# cslr_usb_001 register map
Vendor: Texas Instruments
Peripheral module from a debugger description file.
Registers are 32-bit, access not given, reset values left out (the file's numbers can be read two ways) unless marked. A register's access mark holds for its fields unless they carry their own. Offsets are as the file gives them; lines under a group give offsets from that group; [hi:lo] are bit positions; {n}, {i} and the like mark numbered series; 'fields as' and 'values as' point back to an identical list; <NAME> marks a mode.

## USB (part 1 of 2) — USB2.0 OTG Controller
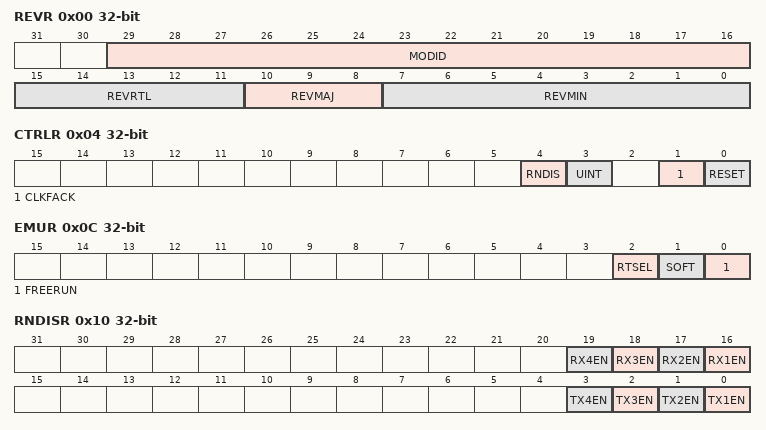
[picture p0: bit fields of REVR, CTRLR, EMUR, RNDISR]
0x00 REVR — Revision Register
  [29:16] MODID ro — Module ID field
  [15:11] REVRTL rw — RTL version
  [10:8] REVMAJ rw — Major revision
  [7:0] REVMIN rw — Minor revision.
0x04 CTRLR — Control Register
  [4] RNDIS rw — RNDIS mode enable
  [3] UINT rw — USB non-PDR interrupt enable
  [1] CLKFACK rw — Clock stop fast ack enable
  [0] RESET wo — Soft reset Writing a 1 starts a module reset
0x08 STATR — Status Register
  [0] DRVVBUS ro — Current DRVVBUS value
0x0C EMUR — Emulation Register to configure CBA3.0 interface
  [2] RTSEL rw — Real-time Enable
  [1] SOFT rw — Soft Stop Enable
  [0] FREERUN rw — Free Run Enable
0x10 RNDISR — RNDIS Register to enable RNDIS mode for each endpoint. Using the global RNDIS enable (RNDIS bit of CTRLR) overrides thie register and enable RNDIS mode for all endpoints
  [n+15] RX{n}EN rw (n=1..4) — Rx Endpoint {n} RNDIS mode enable
  [n-1] TX{n}EN rw (n=1..4) — TX Endpoint {n} RNDIS mode enable
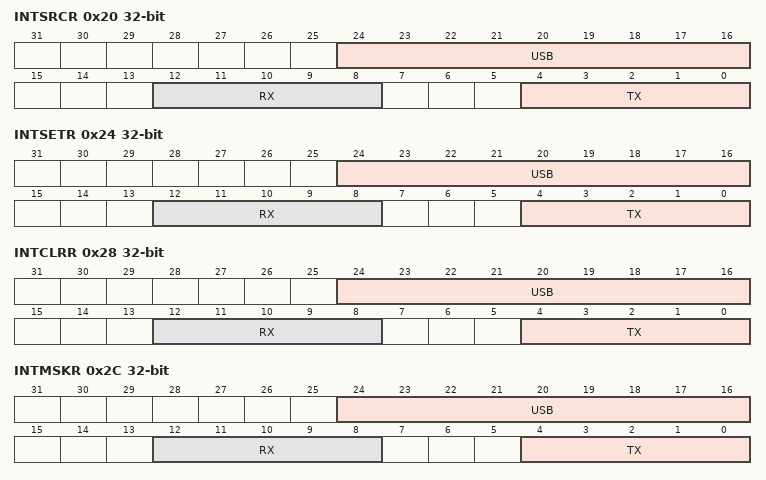
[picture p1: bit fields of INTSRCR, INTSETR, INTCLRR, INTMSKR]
0x20 INTSRCR — USB Interrupt Source Register
  [24:16] USB ro — USB interrupt sources Generated by the USB core (not the DMA)
  [12:8] RX ro — RX endpoint interrupt sources Generated by the USB core (not the DMA)
  [4:0] TX ro — TX endpoint interrupt sources Generated by the USB core (not the DMA)
0x24 INTSETR — USB Interrupt Source Set Register
  [24:16] USB wo — Write a 1 to set equivalent USB interrupt source Allows the USB interrupt sources to be manually triggered
  [12:8] RX wo — Write a 1 to set equivalent RX endpoint interrupt source Allows the USB interrupt sources to be manually triggered
  [4:0] TX wo — Write a 1 to set equivalent TX endpoint interrupt source Allows the USB interrupt sources to be manually triggered
0x28 INTCLRR — USB Interrupt Source Clear Register
  [24:16] USB wo — Write a 1 to clear equivalent USB interrupt source Allows the CPU to acknowledge an interrupt source and turn it off
  [12:8] RX wo — Write a 1 to clear equivalent RX endpoint interrupt source Allows the CPU to acknowledge an interrupt source and turn it off
  [4:0] TX wo — Write a 1 to clear equivalent TX endpoint interrupt source Allows the CPU to acknowledge an interrupt source and turn it off
0x2C INTMSKR — USB Interrupt Mask Register
  [24:16] USB ro — USB interrupt source masks Contains the masks of the interrupt sources generated by the USB core (not the DMA). These masks are used to enable or disable interrupt sources appearing as masked interrupts
  [12:8] RX ro — RX endpoint interrupt source masks Contains the masks of the interrupt sources generated by the USB core (not the DMA). These masks are used to enable or disable interrupt sources appearing as masked interrupts
  [4:0] TX ro — TX endpoint interrupt source masks Contains the masks of the interrupt sources generated by the USB core (not the DMA). These masks are used to enable or disable interrupt sources appearing as masked interrupts
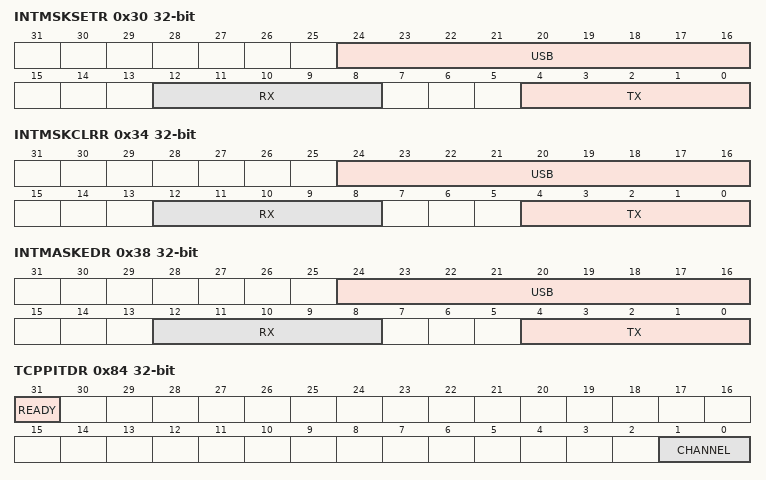
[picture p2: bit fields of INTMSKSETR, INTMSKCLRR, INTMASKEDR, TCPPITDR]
0x30 INTMSKSETR — USB Interrupt Mask Set Register
  [24:16] USB wo — Write a 1 to set equivalent USB interrupt mask Allows the USB interrupt masks to be individually enabled
  [12:8] RX wo — Write a 1 to set equivalent RX endpoint interrupt mask Allows the USB interrupt masks to be individually enabled
  [4:0] TX wo — Write a 1 to set equivalent TX endpoint interrupt mask Allows the USB interrupt masks to be individually enabled
0x34 INTMSKCLRR — USB Interrupt Mask Clear Register
  [24:16] USB wo — Write a 1 to clear equivalent USB interrupt mask Allows the USB interrupt masks to be individually disabled
  [12:8] RX wo — Write a 1 to clear equivalent RX endpoint interrupt mask Allows the USB interrupt masks to be individually disabled
  [4:0] TX wo — Write a 1 to clear equivalent TX endpoint interrupt mask Allows the USB interrupt masks to be individually disabled
0x38 INTMASKEDR — USB Interrupt Source Masked Register
  [24:16] USB ro — USB interrupt sources masked Contains the status of the interrupt sources generated by the USB core masked by the USB Interrupt Mask Register values
  [12:8] RX ro — RX endpoint interrupt sources masked Contains the status of the interrupt sources generated by the USB core masked by the USB Interrupt Mask Register values
  [4:0] TX ro — TX endpoint interrupt sources masked Contains the status of the interrupt sources generated by the USB core masked by the USB Interrupt Mask Register values
0x3C EOIR — USB End of Interrupt Register
  [7:0] VECTOR rw — EOI Vector Allows the CPU to acknowledge completion of an interrupt by writing to the EOI. An eoi_write signal will be generated, the EOI vector will be updated to the written value, and another interrupt will be triggered if interrupt sources remain
0x40 INTVECTR ro — USB Interrupt Vector Register
  [31:0] VECTOR — Input Interrupt Vector Recycles the Interrupt Vector input to be read by the CPU
0x80 TCPPICR — Tx CPPI Control Register
  [0] TCPPI_ENABLE rw — Tx CPPI Enable Controls if the Tx CPPI DMA controller is enabled 0: Tx CPPI DMA is disabled 1: Tx CPPI DMA is enabled
0x84 TCPPITDR — Tx CPPI Teardown Register
  [31] READY ro — Indicates if the Teardown register can be written
  [1:0] CHANNEL rw — Teardown Channel Indicates the channel that is to be torn down
0x88 TCPPIEOIR access per field — Tx CPPI DMA Controller End of Interrupt Register
  [7:0] VECTOR rw — End of Interrupt Vector This is an application specific register which is essentially a general purpose output from the LCSAR. One cycle after this register is written, the eoi_vector[7:0] value will appear on the eoi_vector output port from the LCSAR and the eoi_write output port will be assserted for 1 clock cycle. This register is used to convert level sensitive interrupts to pulsed, non-redundant interrupts
0x8C TCPPIIVECTR ro — Tx CPPI DMA Controller Interrupt Vector Register
  [31:0] VECTOR — Interrupt Vector This is an application specific register which is essentially a general purpose input to the LCSAR. The intr_vector field in this register is a registered version of the intr_vector primary input to the LCSAR. This register is used for interrupt handling
0x90 TCPPIMSKSR — Tx CPPI Masked Status Register
  [3:0] COMP_PENDING ro — Masked High Priority Transmit Completion Pending Indicators for channels 3 to 0 Raw Tx high priority completion indicators bitwise anded with Tx high priority completion mask bits
0x94 TCPPIRAWSR — Tx CPPI Raw Status Register
  [3:0] COMP_PENDING ro — Raw High Priority Transmit Completion Pending Indicators for channels 3 to 0 Active high flags which indicate that a packet has completed transmission on the high priority queue
0x98 TCPPIIENSETR — Tx CPPI Interrupt Enable Set Register
  [3:0] COMP_PENDING_INTR_EN rw — Tx CPPI High Priority Interrupt Enables These are active high interrupt enables corresponding to the Tx CPPI High Priority Completion Pending status bits
0x9C TCPPIIENCLRR — Tx CPPI Interrupt Enable Clear Register
  [3:0] COMP_PENDING_INTR_EN rw — Writing a 1 to any of the bits in the Tx CPPI Interrupt Enable Clear Register will result in clearing of the corresponding bit in the Tx CPPI High Priority Interrupt Enable Register
0xC0 RCPPICR — Rx CPPI Control Register
  [0] RCPPI_ENABLE rw — Rx CPPI Enable Controls if the Rx CPPI DMA controller is enabled 0: Rx CPPI DMA is disabled 1: Rx CPPI DMA is enabled
0xD0 RCPPIMSKSR — Rx CPPI Masked Status Register
  [3:0] MASKED_COMP_PENDING ro — Masked Receive Completion Pending Indicators for channels 3 to 0 Raw Rx completion indicators bitwise ANDed with Rx completion mask bits
0xD4 RCPPIRAWSR — Rx CPPI Raw Status Register
  [3:0] COMP_PENDING ro — Raw Receive Completion Pending Indicators for channels 3 to 0 Active high flags which indicate that a packet has completed reception
0xD8 RCPPIENSETR — Rx CPPI Interrupt Enable Set Register
  [3:0] COMP_PENDING_INTR_EN rw — Rx CPPI Interrupt Enables These are active high interrupt enables corresponding to the Rx CPPI Completion Pending status bits Writing a 1 to any of the bits in the Rx CPPI Interrupt Enable Set Register will result in setting of the corresponding bit in the Rx CPPI Interrupt Enable Register
0xDC RCPPIIENCLRR — Rx CPPI Interrupt Enable Clear Register
  [3:0] COMP_PENDING_INTR_EN rw — Rx CPPI Interrupt Enables These are active high interrupt enables corresponding to the Rx CPPI Completion Pending status bits Writing a 1 to any of the bits in the Rx CPPI Interrupt Enable Clear Register will result in clearing of the corresponding bit in the Rx CPPI Interrupt Enable Register
{0xE0+4i} RBUFCNT{i} (i=0..2) — Rx Buffer Count {i} Register
  [15:0] BUFCNT rw — Rx CPPI Buffer Count The current count of CPPI buffers in Rx channel {i} queue. Writes add to current value (not overwrite)
0xEC RBUFCNT3 — Rx Buffer Count 3 Register
  [15:0] BUFCNT rw — Rx CPPI Buffer Count 0 The current count of CPPI buffers in Rx channel 3 queue. Writes add to current value (not overwrite)
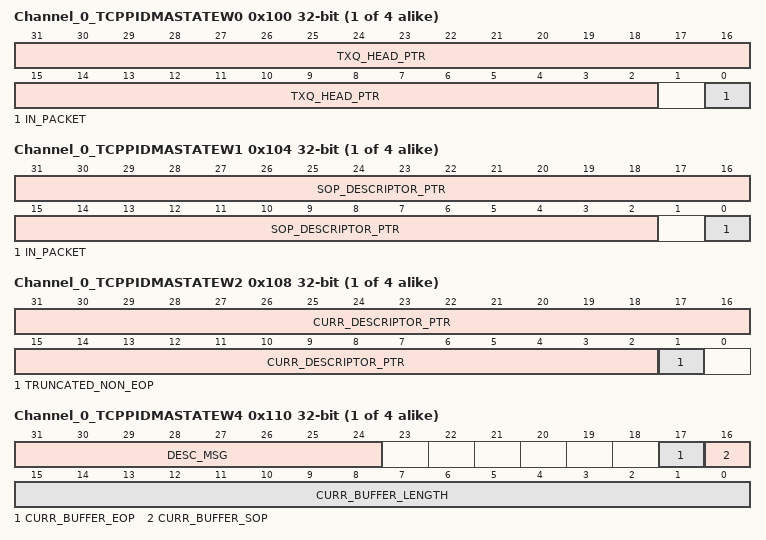
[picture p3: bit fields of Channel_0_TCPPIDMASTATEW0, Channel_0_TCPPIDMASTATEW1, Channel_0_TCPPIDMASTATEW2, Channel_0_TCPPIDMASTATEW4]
{0x100+0x40*i} Channel_{i}_TCPPIDMASTATEW0 (i=0..3) — TX CPPI DMA State Word 0
  [31:2] TXQ_HEAD_PTR rw — TX queue head pointer 30 bit pointer to 32-bit aligned descriptor at the head of the high priority TX queue
  [0] IN_PACKET rw — Flag indicating the DMA is in the middle of processing a packet 0: Not currently in packet 1: Currently in packet
{0x104+0x40*i} Channel_{i}_TCPPIDMASTATEW1 (i=0..3) — TX CPPI DMA State Word 1
  [31:2] SOP_DESCRIPTOR_PTR rw — Start of Packet Buffer Descriptor Pointer 30 bit pointer to 32-bit aligned descriptor which is the first descriptor for the current packet
  [0] IN_PACKET rw — Flag indicating the DMA is in the middle of processing a packet 0: Not currently in packet 1: Currently in packet
{0x108+0x40*i} Channel_{i}_TCPPIDMASTATEW2 (i=0..3) — TX CPPI DMA State Word 2
  [31:2] CURR_DESCRIPTOR_PTR — Current Buffer Descriptor Pointer 30 bit pointer to 32-bit aligned descriptor for buffer from which data is currently being transmitted
  [1] TRUNCATED_NON_EOP — Flag indicating that packet truncation has occurred on the current packet within a buffer which was not designated as the end of packet buff 0: Truncation within non end of packet buffer has not occurred 1: Truncation within non end of packet has occurred
{0x10C+0x40*i} Channel_{i}_TCPPIDMASTATEW3 (i=0..3) — TX CPPI DMA State Word 3
  [31:0] CURR_BUFFER_PTR — Current Buffer Pointer 32 bit absolute byte address in buffer from which data is currently being transmitted
{0x110+0x40*i} Channel_{i}_TCPPIDMASTATEW4 (i=0..3) — TX CPPI DMA State Word 4
  [31:24] DESC_MSG rw — Descriptor Message Byte which is passed from the SOP Tx Descriptor to the SOP Rx descriptor. Used to tag packets
  [17] CURR_BUFFER_EOP rw — Current Buffer is EOP Flag indicating whether or not the current buffer that is being transmitted from is the end of packet buffer
  [16] CURR_BUFFER_SOP rw — Current Buffer is SOP Flag indicating whether or not the current buffer that is being transmitted from is the start of packet buffer
  [15:0] CURR_BUFFER_LENGTH rw — Current Buffer Length Indicates how many valid bytes remain in the current buffer that is being transmitted from
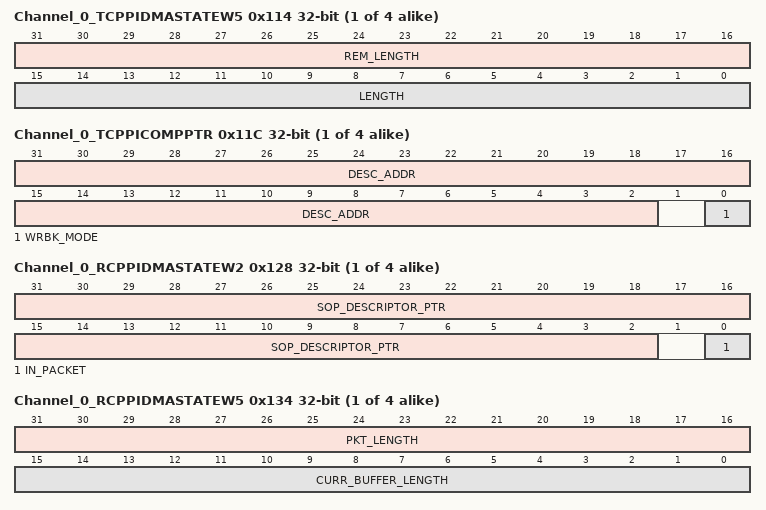
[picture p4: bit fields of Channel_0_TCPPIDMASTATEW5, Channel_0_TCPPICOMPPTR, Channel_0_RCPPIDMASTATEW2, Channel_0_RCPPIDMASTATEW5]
{0x114+0x40*i} Channel_{i}_TCPPIDMASTATEW5 rw (i=0..3) — TX CPPI DMA State Word 5
  [31:16] REM_LENGTH — Remaining Packet Length Indicates how many bytes remain to be transmitted in the packet before truncation occurs
  [15:0] LENGTH — Packet Length Indicates how many bytes are contained in the packet. This value is copied from the packet_length field in Word 3 of the SOP Descriptor. This value is written into the AAL5 trailer for the packet
{0x11C+0x40*i} Channel_{i}_TCPPICOMPPTR (i=0..3) — TX CPPI Completion Pointer
  [31:2] DESC_ADDR rw — Descriptor Address This field contains the 30 bit word aligned pointer of the end of packet descriptor that the DMA has has last processed
  [0] WRBK_MODE rw — Writeback / Compare Mode This bit controls the action that is to be taken when this location is written 0: Compare Mode, Indicates that the value that is presented on bits 31:2 of the write data should be compared against the value that is currently contained in bits 31:2 of this location. If the two match, the interrupt bit corresponding to this Tx Queue should be deasserted 1: Writeback Mode, Indicates that the value that is presented on bits 31:2 of the write data should be written to this location and the interrupt for this Tx Queue should be asserted This bit is read as zero
{0x120+0x40*i} Channel_{i}_RCPPIDMASTATEW0 (i=0..3) — RX CPPI DMA State Word 0
  [7:0] SOP_BUFFER_OFFSET rw — Start of Packet Buffer Offset Controls how many bytes the RX DMA will skip at the beginning of the start of packet buffer before beginning to fill the buffer with receive data. This field is programmed by the Host software when the channel is set up to facilitate addition of various protocol encapsulation headers for retransmission of received packets
{0x124+0x40*i} Channel_{i}_RCPPIDMASTATEW1 (i=0..3) — RX CPPI DMA State Word 1
  [31:2] RXQ_HEAD_PTR rw — RX queue head pointer 30 bit pointer to 32-bit aligned descriptor at the head of the Rx queue
{0x128+0x40*i} Channel_{i}_RCPPIDMASTATEW2 (i=0..3) — RX CPPI DMA State Word 2
  fields as Channel_0_TCPPIDMASTATEW1
{0x12C+0x40*i} Channel_{i}_RCPPIDMASTATEW3 (i=0..3) — RX CPPI DMA State Word 3
  [31:2] CURR_DESCRIPTOR_PTR rw — Current Buffer Descriptor Pointer 30 bit pointer to 32-bit aligned descriptor for buffer into which data is currently being received
{0x130+0x40*i} Channel_{i}_RCPPIDMASTATEW4 rw (i=0..3) — RX CPPI DMA State Word 4
  [31:0] CURR_BUFFER_PTR — Current Buffer Pointer 32 bit absolute byte address in buffer into which data is currently being received
{0x134+0x40*i} Channel_{i}_RCPPIDMASTATEW5 rw (i=0..3) — RX CPPI DMA State Word 5
  [31:16] PKT_LENGTH — Packet Length Indicates how many bytes are contained in the packet. This value is written into bits 15:0 of Word 3 of the SOP Descriptor during end of packet processing
  [15:0] CURR_BUFFER_LENGTH — Current Buffer Length Indicates how many free bytes remain in the current buffer that is being received into
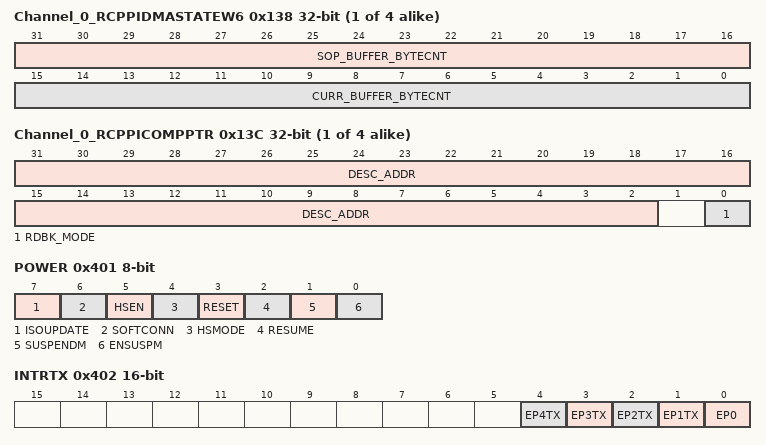
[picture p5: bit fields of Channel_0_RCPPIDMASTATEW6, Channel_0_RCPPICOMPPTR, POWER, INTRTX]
{0x138+0x40*i} Channel_{i}_RCPPIDMASTATEW6 rw (i=0..3) — RX CPPI DMA State Word 6
  [31:16] SOP_BUFFER_BYTECNT — Start of Packet Buffer Byte Count Indicates how many valid bytes are contained in the start of packet buffer
  [15:0] CURR_BUFFER_BYTECNT — Current Buffer Byte Count Indicates how many valid bytes are contained in the buffer that is currently being received into
{0x13C+0x40*i} Channel_{i}_RCPPICOMPPTR (i=0..3) — RX CPPI Completion Pointer
  [31:2] DESC_ADDR rw — Descriptor Address This field contains the 30 bit word aligned pointer of the end of packet descriptor that the DMA has has last processed
  [0] RDBK_MODE rw — Readback / Compare Mode This bit controls the action that is to be taken when this location is read 0: Compare Mode, Indicates that the value that is presented on bits 31:2 of the read data should be compared against the value that is currently contained in bits 31:2 of this location. If the two match, the interrupt bit corresponding to this Rx Queue should be deasserted 1: Readback Mode, Indicates that the value that is presented on bits 31:2 of the read data should be read from this location and the interrupt for this Rx Queue should be asserted This bit is read as zero
0x400 FADDR 8-bit — Function address register
  [6:0] FUNCADDR rw — 7-bit address of the peripheral part of the transaction When used in Peripheral mode (DevCtl.D2=0), this register should be written with the address received through a SET_ADDRESS command, which will then be used for decoding the function address in subsequent token packets When used in Host mode (DevCtl.D2=1), this register should be set to the value sent in a SET_ADDRESS command during device enumeration as the address for the peripheral device
0x401 POWER 8-bit access per field — Power management register
  [7] ISOUPDATE rw — When set, the USB controller will wait for an SOF token from the time TxPktRdy is set before sending the packet. If an IN token is received before an SOF token, then a zero length data packet will be sent Note: Only valid in Peripheral Mode. Also, this bit only affects endpoints performing Isochronous transfers
  [6] SOFTCONN rw — If Soft Connect/Disconnect feature is enabled, then the USB D+/D- lines are enabled when this bit is set and tri-stated when this bit is cleared Note: Only valid in Peripheral Mode
  [5] HSEN rw — When set, the USB controller will negotiate for High-speed mode when the device is reset by the hub. If not set, the device will only operate in Full-speed mode
  [4] HSMODE ro — This bit is set when the USB contoller has successfully negotiated for High-speed mode
  [3] RESET rw — This bit is set when Reset signaling is present on the bus Note: This bit is Read/Write in Host Mode but Read-Only in Peripheral Mode
  [2] RESUME rw — Set to generate Resume signaling when the controller is in Suspend mode. The bit should be cleared after 10 ms (a maximum of 15 ms) to end Resume signaling. In Host mode, this bit is also automatically set when Resume signaling from the target is detected while the USB controller is suspended
  [1] SUSPENDM rw — In Host mode, this bit should be set to enter Suspend mode. In Peripheral mode, this bit is set on entry into Suspend mode. It is cleared when the interrupt register is read, or the RESUME bit is set
  [0] ENSUSPM rw — Set to enable the SUSPENDM output
0x402 INTRTX 16-bit — Interrupt register for Endpoint 0 plus Tx Endpoints 1 to 4
  [n] EP{n}TX ro (n=1..4) — Tx Endpoint {n} interrupt active
  [0] EP0 ro — Endpoint 0 interrupt active
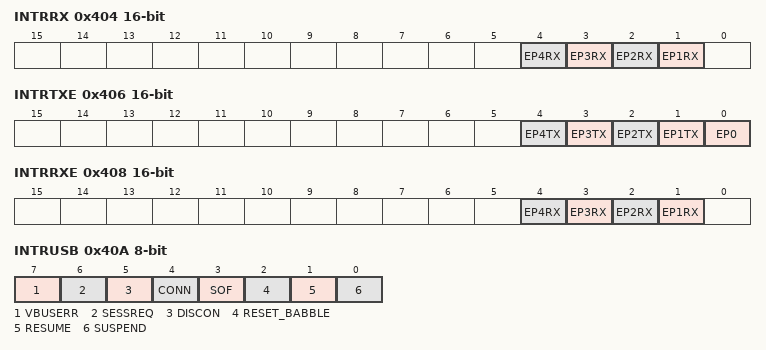
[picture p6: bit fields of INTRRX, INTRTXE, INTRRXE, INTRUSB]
0x404 INTRRX 16-bit — Interrupt register for Rx Endpoints 1 to 4
  [n] EP{n}RX ro (n=1..4) — Rx Endpoint {n} interrupt active
0x406 INTRTXE 16-bit — Interrupt enable register for INTRTX
  [n] EP{n}TX rw (n=1..4) — Tx Endpoint {n} interrupt enable
  [0] EP0 rw — Endpoint 0 interrupt enable
0x408 INTRRXE 16-bit — Interrupt enable register for INTRRX
  [n] EP{n}RX rw (n=1..4) — Rx Endpoint {n} interrupt enable
0x40A INTRUSB 8-bit ro — Interrupt register for common USB interrupts
  [7] VBUSERR — Set when VBus drops below the VBus Valid threshold during a session Only valid when USB controller is 'A' device All active interrupts will be cleared when this register is read
  [6] SESSREQ — Set when Session Request signaling has been detected Only valid when USB controller is 'A' device
  [5] DISCON — Set in Host mode when a device disconnect is detected Set in Peripheral mode when a session ends
  [4] CONN — Set when a device connection is detected Only valid in Host mode
  [3] SOF — Set when a new frame starts
  [2] RESET_BABBLE — Set in Peripheral mode when Reset signaling is detected on the bus Set in Host mode when babble is detected
  [1] RESUME — Set when Resume signaling is detected on the bus while the USB controller is in Suspend mode
  [0] SUSPEND — Set when Suspend signaling is detected on the bus Only valid in Peripheral mode
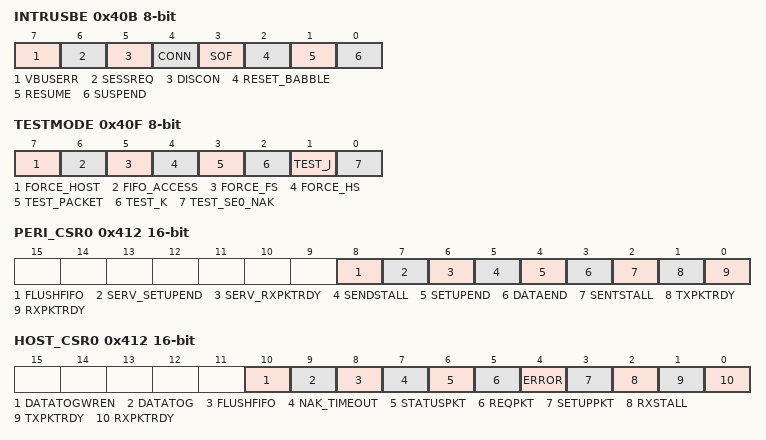
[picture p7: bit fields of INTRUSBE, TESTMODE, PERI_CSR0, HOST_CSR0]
0x40B INTRUSBE 8-bit rw — Interrupt enable register for INTRUSB
  [7] VBUSERR — Vbus error interrupt enable
  [6] SESSREQ — Session request interrupt enable
  [5] DISCON — Disconnect interrupt enable
  [4] CONN — Connect interrupt enable
  [3] SOF — Start of frame interrupt enable
  [2] RESET_BABBLE — Reset interrupt enable
  [1] RESUME — Resume interrupt enable
  [0] SUSPEND — Suspend interrupt enable
0x40C FRAME 16-bit — Frame number register
  [10:0] FRAMENUMBER ro — Last received frame number
0x40E INDEX 8-bit — Index register for selecting the endpoint status and control registers
  [3:0] EPSEL rw — Each Tx endpoint and each Rx endpoint have their own set of control/status registers. EPSEL determines which endpoint control/status registers are accessed Before accessing an endpoint's control/status registers, the endpoint number should be written to the Index register to ensure that the correct control/status registers appear in the memory map
0x40F TESTMODE 8-bit access per field — Register to enable the USB 2.0 test modes
  [7] FORCE_HOST rw — Set this bit to forcibly put the USB controller into Host mode when SESSION bit is set, regardless of whether it is connected to any peripheral. The controller remains in Host mode until the Session bit is cleared, even if a device is disconnected. And if the FORCE_HOST but remains set, it will re-enter Host mode next time the SESSION bit is set. The operating speed is determined using the FORCE_HS and FORCE_FS bits
  [6] FIFO_ACCESS wo — Set this bit to transfer the packet in EP0 Tx FIFO to EP0 Rx FIFO. It is cleared automatically
  [5] FORCE_FS rw — Set this bit to force the USB controller into Full-speed mode when it receives a USB reset
  [4] FORCE_HS rw — Set this bit to force the USB controller into High-speed mode when it receives a USB reset
  [3] TEST_PACKET rw — Set this bit to enter the Test_Packet test mode. In this mode, the USB controller repetitively transmits on the bus a 53-byte test packet, the form of which is defined in the Universal Serial Bus Specification Revision 2.0 Note: The test packet has a fixed format and must be loaded into the Endpoint 0 FIFO before the test mode is entered
  [2] TEST_K rw — Set this bit to enter the Test_K test mode. In this mode, the USB controller transmits a continuous K on the bus
  [1] TEST_J rw — Set this bit to enter the Test_J test mode. In this mode, the USB controller transmits a continuous J on the bus
  [0] TEST_SE0_NAK rw — Set this bit to enter the Test_SE0_NAK test mode. In this mode, the USB controller remains in High-speed mode but responds to any valid IN token with a NAK
0x410 TXMAXP 16-bit — Maximum packet size for peripheral/host Tx endpoint (Index register set to select Endpoints 1 - 4 only)
  [10:0] MAXPAYLOAD rw — The maximum payload transmitted in a single transaction The value set can be up to 1024 bytes but is subject to the constraints placed by the USB Specification on packet sizes for Bulk, Interrupt and Isochronous transfers in Full-speed and High-speed operations The value written to this register should match the wMaxPacketSize field of the Standard Endpoint Descriptor for the associated endpoint. A mismatch could cause unexpected results
0x412 PERI_CSR0 16-bit — Control Status register for Endpoint 0 in Peripheral mode. (Index register set to select Endpoint 0)
  [8] FLUSHFIFO wo — Set this bit to flush the next packet to be transmitted/read from the Endpoint 0 FIFO. The FIFO pointer is reset and the TXPKTRDY/RXPKTRDY bit (below) is cleared Note: FLUSHFIFO has no effect unless TXPKTRDY/RXPKTRDY is set
  [7] SERV_SETUPEND wo — Set this bit to clear the SETUPEND bit. It is cleared automatically
  [6] SERV_RXPKTRDY wo — Set this bit to clear the RXPKTRDY bit. It is cleared automatically
  [5] SENDSTALL wo — Set this bit to terminate the current transaction. The STALL handshake will be transmitted and then this bit will be cleared automatically
  [4] SETUPEND ro — This bit will be set when a control transaction ends before the DATAEND bit has been set. An interrupt will be generated and the FIFO flushed at this time. The bit is cleared by the user writing a 1 to the SERV_SETUPEND bit
  [3] DATAEND wo — Set this bit 1. When setting TXPKTRDY for the last data packet 2. When clearing RXPKTRDY after unloading the last data packet 3. When setting TXPKTRDY for a zero length data packet It is cleared automatically
  [2] SENTSTALL rw — This bit is set when a STALL handshake is transmitted. This bit should be cleared by the user
  [1] TXPKTRDY rw — Set this bit after loading a data packet into the FIFO. It is cleared automatically when the data packet has been transmitted. An interrupt is generated (if enabled) when the bit is cleared
  [0] RXPKTRDY ro — This bit is set when a data packet has been received. An interrupt is generated when this bit is set. This bit is cleared by setting the SERV_RXPKTRDY bit
0x412 HOST_CSR0 16-bit — Control Status register for Endpoint 0 in Host mode. (Index register set to select Endpoint 0)
  [10] DATATOGWREN wo — Write 1 to this bit to enable the DATATOG bit to be written. This bit is automatically cleared once the new value is written to DATATOG
  [9] DATATOG rw — When read, this bit indicates the current state of the EP0 data toggle. If DATATOGWREN is high, this bit canbe written with the required setting of the data toggle. If DATATOGWREN is low, any value written to this bit is ignored
  [8] FLUSHFIFO wo — Write 1 to this bit to flush the next packet to be transmitted/read from the Endpoint 0 FIFO. The FIFO pointer is reset and the TXPKTRDY/RXPKTRDY bit (below) is cleared Note: FLUSHFIFO has no effect unless TXPKTRDY/RXPKTRDY is set
  [7] NAK_TIMEOUT wo — This bit will be set when Endpoint 0 is halted following the receipt of NAK responses for longer than the time set by the NAKLIMIT0 register. This bit should be cleared to allow the endpoint to continue
  [6] STATUSPKT rw — Set this bit at the same time as the TXPKTRDY or REQPKT bit is set, to perform a status stage transaction. Setting this bit ensures that the data toggle is set to 1 so that a DATA1 packet is used for the Status Stage transaction
  [5] REQPKT rw — Set this bit to request an IN transaction. It is cleared when RXPKTRDY is set
  [4] ERROR wo — This bit will be set when three attempts have been made to perform a transaction with no response from the peripheral. The user should clear this bit. An interrupt is generated when this bit is set
  [3] SETUPPKT rw — Set this bit, at the same time as the TXPKTRDY bit is set, to send a SETUP token instead of an OUT token for the transaction
  [2] RXSTALL rw — This bit is set when a STALL handshake is received. The user should clear this bit
  [1] TXPKTRDY rw — Set this bit after loading a data packet into the FIFO. It is cleared automatically when the data packet has been transmitted. An interrupt is generated (if enabled) when the bit is cleared
  [0] RXPKTRDY rw — This bit is set when a data packet has been received. An interrupt is generated when this bit is set. Clear this bit by setting the SERV_RXPKTRDY bit
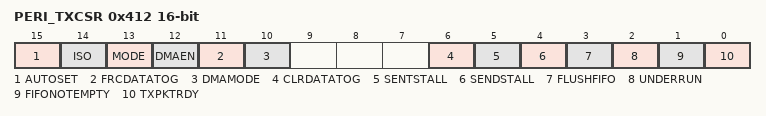
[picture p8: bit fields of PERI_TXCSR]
0x412 PERI_TXCSR 16-bit — Control Status register for peripheral Tx endpoint. (Index register set to select Endpoints 1 - 4)
  [15] AUTOSET rw — When this bit is set, TXPKTRDY will be automatically set when data of the maximum packet size (value in TXMAXP is loaded into the Tx FIFO. If a packet of less than the maximum packet size is loaded, then TXPKTRDY will have to be set manually. TXPKTRDY will also be automatically set when the first of two packets in the Tx FIFO has been sent and the second packet is the maximum packet size
  [14] ISO rw — Set this bit to enable the Tx endpoint for Isochronous transfers, and clear it to enable the Tx endpoint for Bulk or Interrupt transfers
  [13] MODE rw — Set this bit to enable the endpoint direction as Tx, and clear the bit to enable it as Rx Note: This bit only has any effect where the same endpoint FIFO is used for both Tx and Rx transactions
  [12] DMAEN rw — Set this bit to enable the DMA request for the Tx endpoint
  [11] FRCDATATOG rw — Set this bit to force the endpoint data toggle to switch and the data packet to be cleared from the FIFO, regardless of whether an ACK was received. This can be used by Interrupt Tx endpoints that are used to communicate rate feedback for Isochronous endpoints
  [10] DMAMODE rw — This bit should always be 0
  [6] CLRDATATOG wo — Write a 1 to this bit to reset the endpoint data toggle to 0
  [5] SENTSTALL rw — This bit is set automatically when a STALL handshake is transmitted. The FIFO is flushed and the TXPKTRDY bit is cleared (see below). The user should clear this bit
  [4] SENDSTALL rw — Write a 1 to this bit to issue a STALL handshake to an IN token. Clear this bit to terminate the stall condition Note: This bit has no effect where the endpoint is being used for Isochronous transfers
  [3] FLUSHFIFO wo — Write a 1 to this bit to flush the next packet to be transmitted from the endpoint Tx FIFO. The FIFO pointer is reset and the TXPKTRDY bit (below) is cleared. Note: FlushFIFO has no effect unless TXPKTRDY is set. Also note that, if the FIFO is double-buffered, FlushFIFO may need to be set twice to completely clear the FIFO
  [2] UNDERRUN rw — This bit is set automatically if an IN token is received when TXPKTRDY is not set. The user should clear this bit
  [1] FIFONOTEMPTY rw — This bit is set when there is at least 1 packet in the Tx FIFO. The user should clear this bit
  [0] TXPKTRDY rw — Set this bit after loading a data packet into the FIFO. It is cleared automatically when a data packet has been transmitted. An interrupt is generated (if enabled) when the bit is cleared
